# PIC32CX2051MTSH128 device description
Architecture: CORTEX-M4; Family: PIC32CXMT; Series: PIC32CXMTSH
Registers are 32-bit, read-write, no defined reset value unless marked. A register's access mark holds for its fields unless they carry their own. Offsets are from the block's base; [hi:lo] are bit positions; {n}, {i} and the like mark numbered series.

## AES — Advanced Encryption Standard
Instances: AES 0x44000000
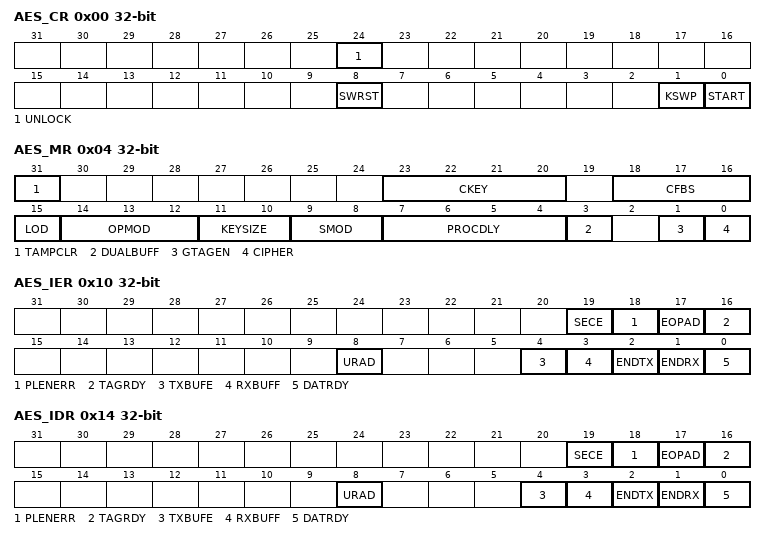
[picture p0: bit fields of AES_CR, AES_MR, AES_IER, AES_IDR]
0x00 AES_CR wo — Control Register
  [24] UNLOCK — Unlock Processing
  [8] SWRST — Software Reset
  [1] KSWP — Key Swap
  [0] START — Start Processing
0x04 AES_MR — Mode Register
  [31] TAMPCLR — Tamper Clear Enable
  [23:20] CKEY — Key
    14=PASSWD (This field must be written with 0xE the first time AES_MR is programmed. For subsequent programming of AES_MR, any value can be written, including that of 0xE. Always reads as 0.)
  [18:16] CFBS — Cipher Feedback Data Size
    0=SIZE_128BIT (128-bit); 1=SIZE_64BIT (64-bit); 2=SIZE_32BIT (32-bit); 3=SIZE_16BIT (16-bit); 4=SIZE_8BIT (8-bit)
  [15] LOD — Last Output Data Mode
  [14:12] OPMOD — Operating Mode
    0=ECB (ECB: Electronic Codebook mode); 1=CBC (CBC: Cipher Block Chaining mode); 2=OFB (OFB: Output Feedback mode); 3=CFB (CFB: Cipher Feedback mode); 4=CTR (CTR: Counter mode (16-bit internal counter)); 5=GCM (GCM: Galois/Counter mode)
  [11:10] KEYSIZE
    0=AES128 (AES Key Size is 128 bits); 1=AES192 (AES Key Size is 192 bits); 2=AES256 (AES Key Size is 256 bits)
  [9:8] SMOD — Start Mode
    0=MANUAL_START (Manual Mode); 1=AUTO_START (Auto Mode); 2=IDATAR0_START (AES_IDATAR0 access only Auto Mode (PDC))
  [7:4] PROCDLY — Processing Delay
  [3] DUALBUFF — Dual Input Buffer
    0=INACTIVE (AES_IDATARx cannot be written during processing of previous block.); 1=ACTIVE (AES_IDATARx can be written during processing of previous block when SMOD = 2. It speeds up the overall runtime of large files.)
  [1] GTAGEN — GCM Automatic Tag Generation Enable
  [0] CIPHER — Processing Mode
0x10 AES_IER wo — Interrupt Enable Register
  [19] SECE — Security and/or Safety Event Interrupt Enable
  [18] PLENERR — Padding Length Error Interrupt Enable
  [17] EOPAD — End of Padding Interrupt Enable
  [16] TAGRDY — GCM Tag Ready Interrupt Enable
  [8] URAD — Unspecified Register Access Detection Interrupt Enable
  [4] TXBUFE — Transmit Buffer Empty Interrupt Enable
  [3] RXBUFF — Receive Buffer Full Interrupt Enable
  [2] ENDTX — End of Transmit Buffer Interrupt Enable
  [1] ENDRX — End of Receive Buffer Interrupt Enable
  [0] DATRDY — Data Ready Interrupt Enable
0x14 AES_IDR wo — Interrupt Disable Register
  [19] SECE — Security and/or Safety Event Interrupt Disable
  [18] PLENERR — Padding Length Error Interrupt Disable
  [17] EOPAD — End of Padding Interrupt Disable
  [16] TAGRDY — GCM Tag Ready Interrupt Disable
  [8] URAD — Unspecified Register Access Detection Interrupt Disable
  [4] TXBUFE — Transmit Buffer Empty Interrupt Disable
  [3] RXBUFF — Receive Buffer Full Interrupt Disable
  [2] ENDTX — End of Transmit Buffer Interrupt Disable
  [1] ENDRX — End of Receive Buffer Interrupt Disable
  [0] DATRDY — Data Ready Interrupt Disable
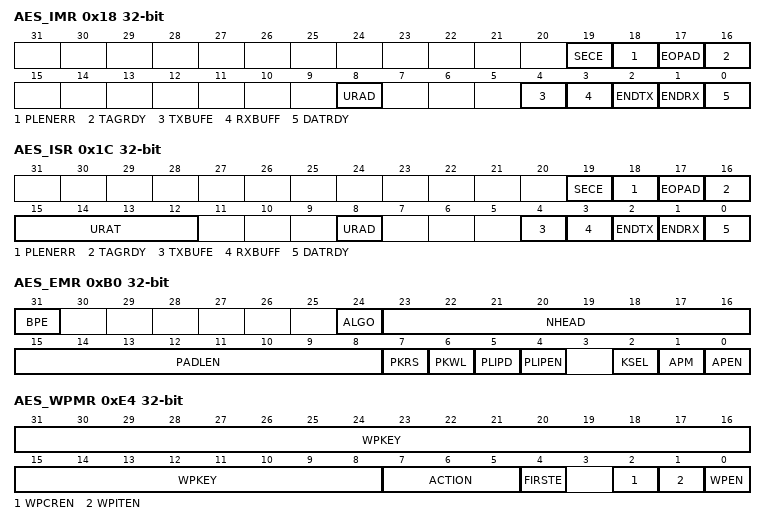
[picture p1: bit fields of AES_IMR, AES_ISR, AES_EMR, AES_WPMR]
0x18 AES_IMR ro — Interrupt Mask Register
  [19] SECE — Security and/or Safety Event Interrupt Mask
  [18] PLENERR — Padding Length Error Interrupt Mask
  [17] EOPAD — End of Padding Interrupt Mask
  [16] TAGRDY — GCM Tag Ready Interrupt Mask
  [8] URAD — Unspecified Register Access Detection Interrupt Mask
  [4] TXBUFE — Transmit Buffer Empty Interrupt Mask
  [3] RXBUFF — Receive Buffer Full Interrupt Mask
  [2] ENDTX — End of Transmit Buffer Interrupt Mask
  [1] ENDRX — End of Receive Buffer Interrupt Mask
  [0] DATRDY — Data Ready Interrupt Mask
0x1C AES_ISR ro — Interrupt Status Register
  [19] SECE — Security and/or Safety Event (cleared on read)
  [18] PLENERR — Padding Length Error
  [17] EOPAD — End of Padding
  [16] TAGRDY — GCM Tag Ready
  [15:12] URAT — Unspecified Register Access (cleared by writing SWRST in AES_CR)
    0=IDR_WR_PROCESSING (Input Data register written during the data processing when SMOD = 2 mode.); 1=ODR_RD_PROCESSING (Output Data register read during the data processing.); 2=MR_WR_PROCESSING (Mode register written during the data processing.); 3=ODR_RD_SUBKGEN (Output Data register read during the sub-keys generation.); 4=MR_WR_SUBKGEN (Mode register written during the sub-keys generation.); 5=WOR_RD_ACCESS (Write-only register read access.)
  [8] URAD — Unspecified Register Access Detection Status (cleared by writing SWRST in AES_CR)
  [4] TXBUFE — TX Buffer Empty (cleared by writing AES_TCR or AES_TNCR)
  [3] RXBUFF — RX Buffer Full (cleared by writing AES_RCR or AES_RNCR)
  [2] ENDTX — End of TX Buffer (cleared by writing AES_TCR or AES_TNCR)
  [1] ENDRX — End of RX Buffer (cleared by writing AES_RCR or AES_RNCR)
  [0] DATRDY — Data Ready (cleared by setting bit START or bit SWRST in AES_CR or by reading AES_ODATARx)
{0x20+4i} AES_KEYWR[{i}] (i=0..7) wo — Key Word Register
  [31:0] KEYW — Key Word
{0x40+4i} AES_IDATAR[{i}] (i=0..3) wo — Input Data Register
  [31:0] IDATA — Input Data Word
{0x50+4i} AES_ODATAR[{i}] (i=0..3) ro — Output Data Register
  [31:0] ODATA — Output Data
{0x60+4i} AES_IVR[{i}] (i=0..3) wo — Initialization Vector Register
  [31:0] IV — Initialization Vector
0x70 AES_AADLENR — Additional Authenticated Data Length Register
  [31:0] AADLEN — Additional Authenticated Data Length
0x74 AES_CLENR — Plaintext/Ciphertext Length Register
  [31:0] CLEN — Plaintext/Ciphertext Length
{0x78+4i} AES_GHASHR[{i}] (i=0..3) — GCM Intermediate Hash Word Register
  [31:0] GHASH — Intermediate GCM Hash Word x
{0x88+4i} AES_TAGR[{i}] (i=0..3) ro — GCM Authentication Tag Word Register
  [31:0] TAG — GCM Authentication Tag x
0x98 AES_CTRR ro — GCM Encryption Counter Value Register
  [31:0] CTR — GCM Encryption Counter
{0x9C+4i} AES_GCMHR[{i}] (i=0..3) — GCM H Word Register
  [31:0] H — GCM H Word x
0xB0 AES_EMR — Extended Mode Register
  [31] BPE — Block Processing End
  [24] ALGO — Encryption Algorithm
    0=AES (The AES algorithm is used for encryption.); 1=ARIA (The ARIA algorithm is used for encryption.)
  [23:16] NHEAD — IPSec Next Header
  [15:8] PADLEN — Auto Padding Length
  [7] PKRS — Private Key Internal Register Select
  [6] PKWL — Private Key Write Lock
  [5] PLIPD — Protocol Layer Improved Performance Decipher
  [4] PLIPEN — Protocol Layer Improved Performance Enable
  [2] KSEL — Key Selection
  [1] APM — Auto Padding Mode
  [0] APEN — Auto Padding Enable
0xB4 AES_BCNT — Byte Counter Register
  [31:0] BCNT — Auto Padding Byte Counter
0xE4 AES_WPMR — Write Protection Mode Register
  [31:8] WPKEY — Write Protection Key
    0x414553=PASSWD (Writing any other value in this field aborts the write operation of the WPEN,WPITEN,WPCREN bits. Always reads as 0.)
  [7:5] ACTION — Action on Abnormal Event Detection
    0=REPORT_ONLY (No action (stop or clear key) is performed when one of PKRPVS, WPVS, CGD, SEQE, or SWE flags is set.); 1=LOCK_PKRPVS_WPVS_SWE (If a processing is in progress when the AES_WPSR.PKRPVS/WPVS/SWE event detection occurs, the current processing is ended normally but no other processing is started while a AES_CR.UNLOCK command is issued.); 2=LOCK_CGD_SEQE (If a processing is in progress when the AES_WPSR.CGD/SEQE event detection occurs, the current processing is ended normally but no other processing is started while a AES_CR.UNLOCK command is issued.); 3=LOCK_ANY_EV (If a processing is in progress when the AES_WPSR.PKRPVS/WPVS/CGD/SEQE/SWE events detection occurs, the current processing is ended normally but no other processing is started while a AES_CR.UNLOCK command is issued.); 4=CLEAR_PKRPVS_WPVS_SWE (If a processing is in progress when the AES_WPSR.PKRPVS/WPVS/SWE events detection occurs, the current processing is ended normally but no other processing is started while a AES_CR.UNLOCK command is issued. Moreover, the AES_KEYWRx key is immediately cleared.); 5=CLEAR_CGD_SEQE (If a processing is in progress when the AES_WPSR.CGD/SEQE events detection occurs, the current processing is ended normally but no other processing is started while a AES_CR.UNLOCK command is issued. Moreover, the AES_KEYWRx key is immediately cleared.); 6=CLEAR_ANY_EV (If a processing is in progress when the AES_WPSR.PKRPVS/WPVS/CGD/SEQE/SWE events detection occurs, the current processing is ended normally but no other processing is started while a AES_CR.UNLOCK command is issued. Moreover, the AES_KEYWRx key is immediately cleared.)
  [4] FIRSTE — First Error Report Enable
  [2] WPCREN — Write Protection Control Enable
  [1] WPITEN — Write Protection Interruption Enable
  [0] WPEN — Write Protection Configuration Enable
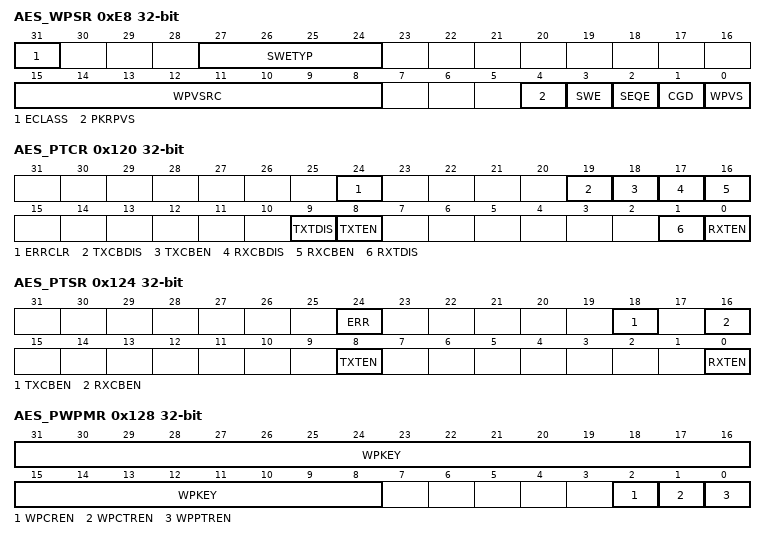
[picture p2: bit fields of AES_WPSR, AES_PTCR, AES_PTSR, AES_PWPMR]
0xE8 AES_WPSR ro — Write Protection Status Register
  [31] ECLASS — Software Error Class (cleared on read)
    0=WARNING (An abnormal access that does not affect system functionality); 1=ERROR (An access is performed into key, input data, control registers while the AES is performing an encryption/decryption or a start is request by software or DMA while the key is not fully configured.)
  [27:24] SWETYP — Software Error Type (cleared on read)
    0=READ_WO (A write-only register has been read (Warning).); 1=WRITE_RO (AES is enabled and a write access has been performed on a read-only register (Warning).); 2=UNDEF_RW (Access to an undefined address (Warning).); 3=CTRL_START (Abnormal use of AES_CR.START command when DMA access is configured.); 4=WEIRD_ACTION (A key write, init value write, output data read, AES_MR and AES_EMR write, GCM configuration registers write, AES_BCNT write, Private Key bus access has been performed while a current processing is in progress (abnormal).); 5=INCOMPLETE_KEY (A tentative of start is required while the key is not fully loaded into the AES_KEYWRx registers.)
  [15:8] WPVSRC — Write Protection Violation Source
  [4] PKRPVS — Private Key Internal Register Protection Violation Status (cleared on read)
  [3] SWE — Software Control Error (cleared on read)
  [2] SEQE — Internal Sequencer Error (cleared on read)
  [1] CGD — Clock Glitch Detected (cleared on read)
  [0] WPVS — Write Protection Violation Status (cleared on read)
0x100 AES_RPR — Receive Pointer Register
  [31:0] RXPTR
0x104 AES_RCR — Receive Counter Register
  [15:0] RXCTR
0x108 AES_TPR — Transmit Pointer Register
  [31:0] TXPTR — Transmit Counter Register
0x10C AES_TCR — Transmit Counter Register
  [15:0] TXCTR
0x110 AES_RNPR — Receive Next Pointer Register
  [31:0] RXNPTR — Receive Next Pointer
0x114 AES_RNCR — Receive Next Counter Register
  [15:0] RXNCTR — Receive Next Counter
0x118 AES_TNPR — Transmit Next Pointer Register
  [31:0] TXNPTR — Transmit Next Pointer
0x11C AES_TNCR — Transmit Next Counter Register
  [15:0] TXNCTR — Transmit Counter Next
0x120 AES_PTCR wo — Transfer Control Register
  [24] ERRCLR — Transfer Bus Error Clear
  [19] TXCBDIS — Transmitter Circular Buffer Disable
  [18] TXCBEN — Transmitter Circular Buffer Enable
  [17] RXCBDIS — Receiver Circular Buffer Disable
  [16] RXCBEN — Receiver Circular Buffer Enable
  [9] TXTDIS — Transmitter Transfer Disable
  [8] TXTEN — Transmitter Transfer Enable
  [1] RXTDIS — Receiver Transfer Disable
  [0] RXTEN — Receiver Transfer Enable
0x124 AES_PTSR ro — Transfer Status Register
  [24] ERR — Transfer Bus Error
  [18] TXCBEN — Transmitter Circular Buffer Enable
  [16] RXCBEN — Receiver Circular Buffer Enable
  [8] TXTEN — Transmitter Transfer Enable
  [0] RXTEN — Receiver Transfer Enable
0x128 AES_PWPMR — Write Protection Mode Register
  [31:8] WPKEY — Write Protection Key
    0x504443=PASSWD (Writing any other value in this field aborts the write operation. Always reads as 0.)
  [2] WPCREN — Write Protection Control Register Enable
  [1] WPCTREN — Write Protection Counter Registers Enable
  [0] WPPTREN — Write Protection Pointer Registers Enable

## MEM2MEM — Memory to Memory
Instances: MEM2MEM0 0x40034000, MEM2MEM1 0x48004000
Registers as AES (with AES read as MEM2MEM), without AES_CR, AES_IER, AES_IDR, AES_IMR, AES_ISR, AES_KEYWR, AES_IDATAR, AES_ODATAR, AES_IVR, AES_AADLENR, AES_CLENR, AES_GHASHR, AES_TAGR, AES_CTRR, AES_GCMHR, AES_EMR, AES_BCNT, AES_WPMR, AES_WPSR; these are added or differ:
0x00 MEM2MEM_THR — Transfer Holding Register
  [31:0] THDATA — Transfer Holding Data
0x04 MEM2MEM_MR — Mode Register
  [1:0] TSIZE — Transfer Size
    0=T_8BIT (The buffer size is defined in bytes.); 1=T_16BIT (The buffer size is defined in half-words (16-bit).); 2=T_32BIT (The buffer size is defined in words (32-bit). Default value.)
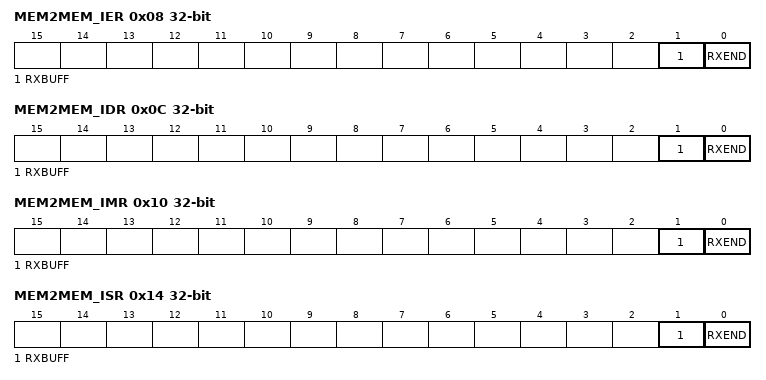
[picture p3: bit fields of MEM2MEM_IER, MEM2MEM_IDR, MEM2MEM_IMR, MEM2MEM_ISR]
0x08 MEM2MEM_IER wo — Interrupt Enable Register
  [1] RXBUFF — Buffer Full Interrupt Enable
  [0] RXEND — End of Transfer Interrupt Enable
0x0C MEM2MEM_IDR wo — Interrupt Disable Register
  [1] RXBUFF — Buffer Full Interrupt Disable
  [0] RXEND — End of Transfer Interrupt Disable
0x10 MEM2MEM_IMR ro — Interrupt Mask Register
  [1] RXBUFF — Buffer Full Interrupt Mask
  [0] RXEND — End of Transfer Interrupt Mask
0x14 MEM2MEM_ISR ro — Interrupt Status Register
  [1] RXBUFF — Buffer Full
  [0] RXEND — End of Transfer
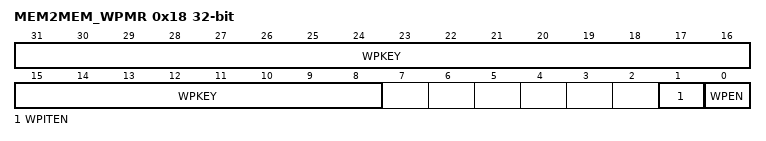
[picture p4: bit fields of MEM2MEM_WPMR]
0x18 MEM2MEM_WPMR — Write Protection Mode Register
  [31:8] WPKEY — Write Protection Key
    0x4D454D=PASSWD (Writing any other value in this field aborts the write operation of the WPEN, WPITEN bits. Always reads as 0.)
  [1] WPITEN — Write Protection Interruption Enable
  [0] WPEN — Write Protection Configuration Enable

## Notices in the file
Copyright %copyright_year% Microchip Technology Inc.
SPDX-License-Identifier: Apache-2.0
Licensed under the Apache License, Version 2.0 (the "License");
you may not use this file except in compliance with the License.
You may obtain a copy of the License at
http://www.apache.org/licenses/LICENSE-2.0
Unless required by applicable law or agreed to in writing, software
distributed under the License is distributed on an "AS IS" BASIS,
WITHOUT WARRANTIES OR CONDITIONS OF ANY KIND, either express or implied.
See the License for the specific language governing permissions and
limitations under the License.
